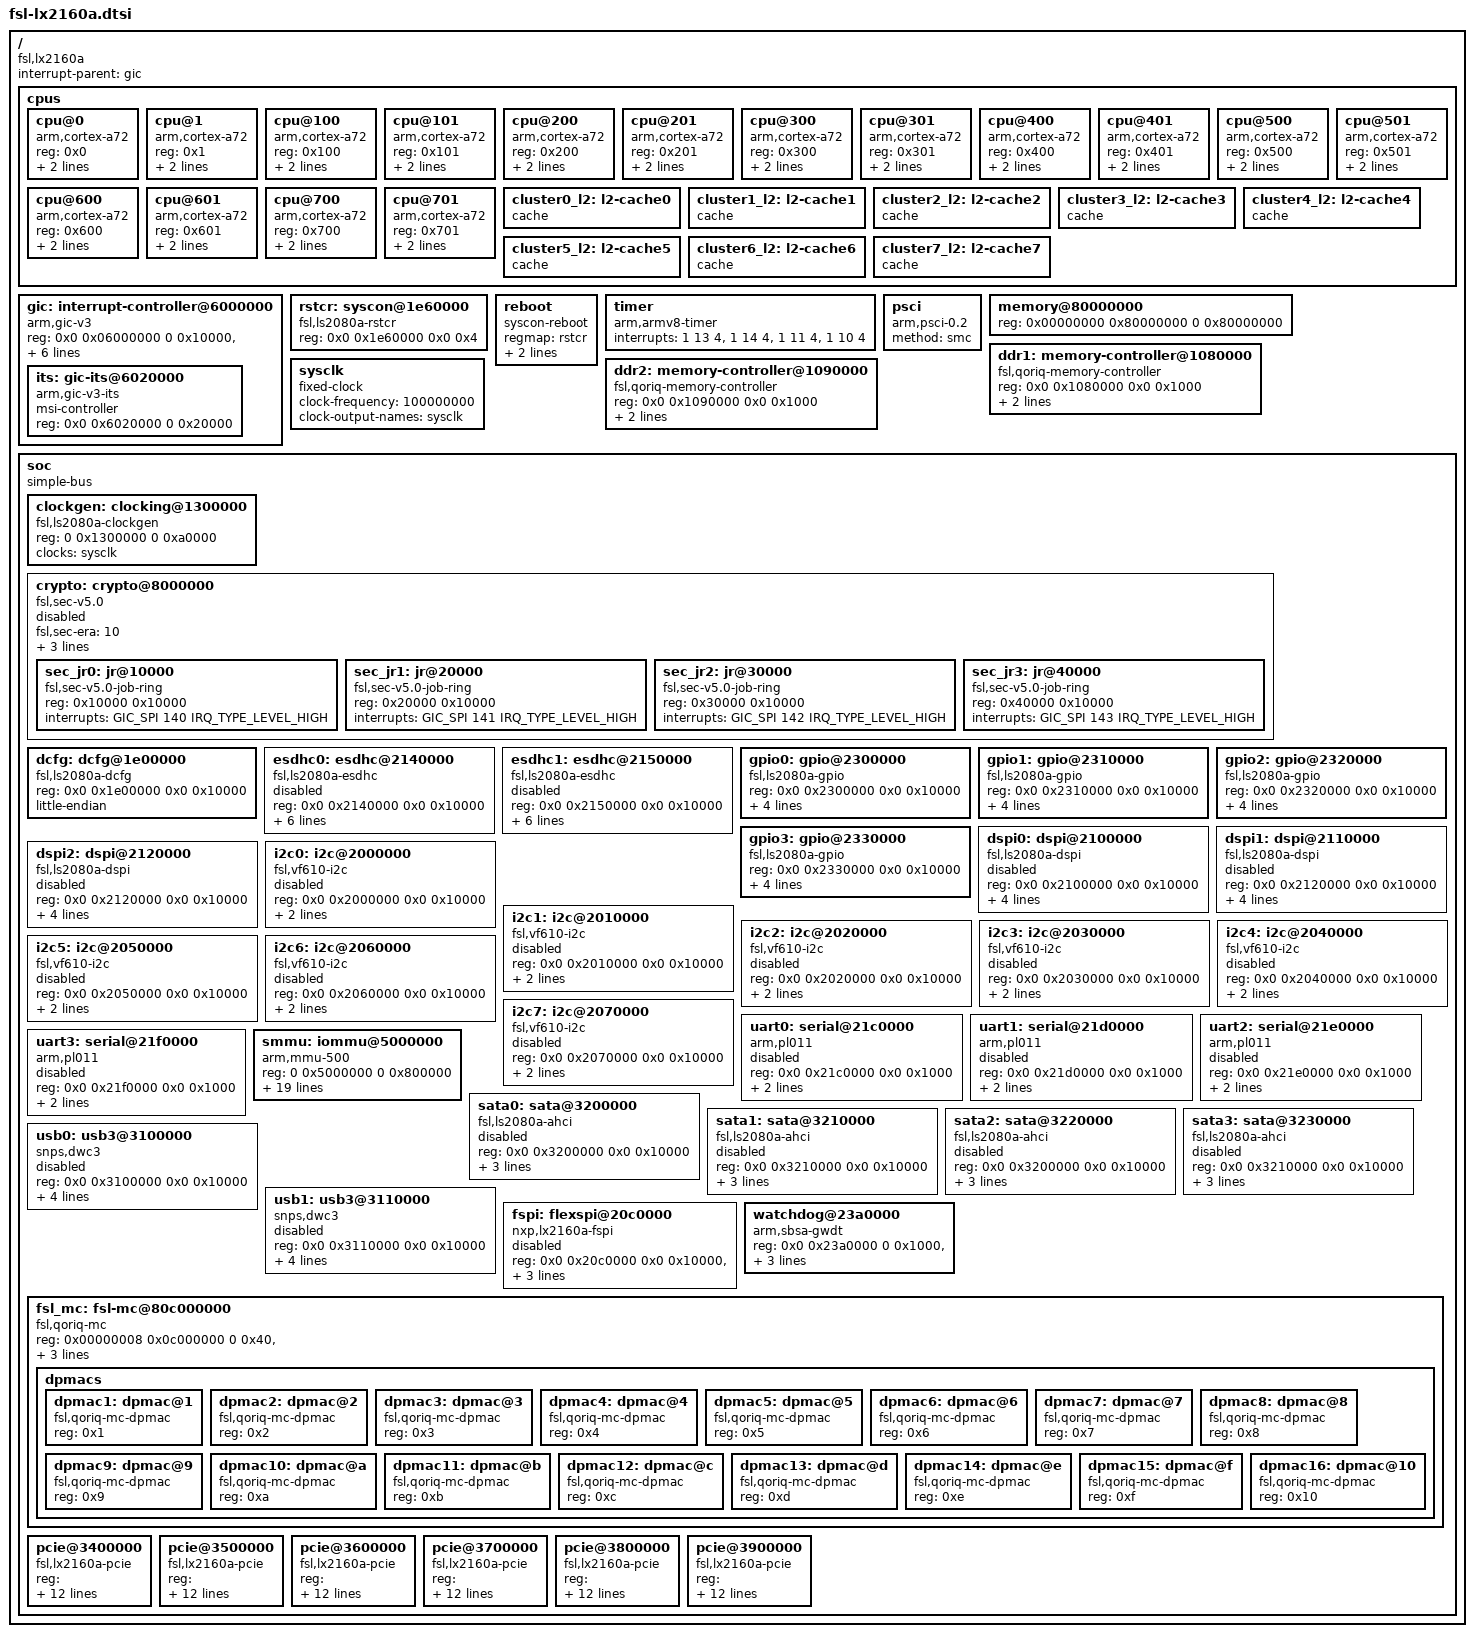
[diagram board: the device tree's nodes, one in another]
/*
 * Device Tree Include file for Layerscape-LX2160A family SoC.
 *
 * Copyright 2018 NXP
 *
 * Sriram Dash <sriram.dash@nxp.com>
 *
 * This file is dual-licensed: you can use it either under the terms
 * of the GPLv2 or the X11 license, at your option. Note that this dual
 * licensing only applies to this file, and not this project as a
 * whole.
 *
 *  a) This library is free software; you can redistribute it and/or
 *     modify it under the terms of the GNU General Public License as
 *     published by the Free Software Foundation; either version 2 of the
 *     License, or (at your option) any later version.
 *
 *     This library is distributed in the hope that it will be useful,
 *     but WITHOUT ANY WARRANTY; without even the implied warranty of
 *     MERCHANTABILITY or FITNESS FOR A PARTICULAR PURPOSE.  See the
 *     GNU General Public License for more details.
 *
 * Or, alternatively,
 *
 *  b) Permission is hereby granted, free of charge, to any person
 *     obtaining a copy of this software and associated documentation
 *     files (the "Software"), to deal in the Software without
 *     restriction, including without limitation the rights to use,
 *     copy, modify, merge, publish, distribute, sublicense, and/or
 *     sell copies of the Software, and to permit persons to whom the
 *     Software is furnished to do so, subject to the following
 *     conditions:
 *
 *     The above copyright notice and this permission notice shall be
 *     included in all copies or substantial portions of the Software.
 *
 *     THE SOFTWARE IS PROVIDED "AS IS", WITHOUT WARRANTY OF ANY KIND,
 *     EXPRESS OR IMPLIED, INCLUDING BUT NOT LIMITED TO THE WARRANTIES
 *     OF MERCHANTABILITY, FITNESS FOR A PARTICULAR PURPOSE AND
 *     NONINFRINGEMENT. IN NO EVENT SHALL THE AUTHORS OR COPYRIGHT
 *     HOLDERS BE LIABLE FOR ANY CLAIM, DAMAGES OR OTHER LIABILITY,
 *     WHETHER IN AN ACTION OF CONTRACT, TORT OR OTHERWISE, ARISING
 *     FROM, OUT OF OR IN CONNECTION WITH THE SOFTWARE OR THE USE OR
 *     OTHER DEALINGS IN THE SOFTWARE.
 */

#include <dt-bindings/interrupt-controller/arm-gic.h>

/memreserve/ 0x80000000 0x00010000;

/ {
	compatible = "fsl,lx2160a";
	interrupt-parent = <&gic>;
	#address-cells = <2>;
	#size-cells = <2>;

	cpus {
		#address-cells = <1>;
		#size-cells = <0>;

		/* We have 8 clusters having 2 Cortex-A72 cores each */
		cpu@0 {
			device_type = "cpu";
			compatible = "arm,cortex-a72";
			reg = <0x0>;
			clocks = <&clockgen 1 0>;
			next-level-cache = <&cluster0_l2>;
		};

		cpu@1 {
			device_type = "cpu";
			compatible = "arm,cortex-a72";
			reg = <0x1>;
			clocks = <&clockgen 1 0>;
			next-level-cache = <&cluster0_l2>;
		};

		cpu@100 {
			device_type = "cpu";
			compatible = "arm,cortex-a72";
			reg = <0x100>;
			clocks = <&clockgen 1 1>;
			next-level-cache = <&cluster1_l2>;
		};

		cpu@101 {
			device_type = "cpu";
			compatible = "arm,cortex-a72";
			reg = <0x101>;
			clocks = <&clockgen 1 1>;
			next-level-cache = <&cluster1_l2>;
		};

		cpu@200 {
			device_type = "cpu";
			compatible = "arm,cortex-a72";
			reg = <0x200>;
			clocks = <&clockgen 1 2>;
			next-level-cache = <&cluster2_l2>;
		};

		cpu@201 {
			device_type = "cpu";
			compatible = "arm,cortex-a72";
			reg = <0x201>;
			clocks = <&clockgen 1 2>;
			next-level-cache = <&cluster2_l2>;
		};

		cpu@300 {
			device_type = "cpu";
			compatible = "arm,cortex-a72";
			reg = <0x300>;
			clocks = <&clockgen 1 3>;
			next-level-cache = <&cluster3_l2>;
		};

		cpu@301 {
			device_type = "cpu";
			compatible = "arm,cortex-a72";
			reg = <0x301>;
			clocks = <&clockgen 1 3>;
			next-level-cache = <&cluster3_l2>;
		};

		cpu@400 {
			device_type = "cpu";
			compatible = "arm,cortex-a72";
			reg = <0x400>;
			clocks = <&clockgen 1 4>;
			next-level-cache = <&cluster4_l2>;
		};

		cpu@401 {
			device_type = "cpu";
			compatible = "arm,cortex-a72";
			reg = <0x401>;
			clocks = <&clockgen 1 4>;
			next-level-cache = <&cluster4_l2>;
		};

		cpu@500 {
			device_type = "cpu";
			compatible = "arm,cortex-a72";
			reg = <0x500>;
			clocks = <&clockgen 1 5>;
			next-level-cache = <&cluster5_l2>;
		};

		cpu@501 {
			device_type = "cpu";
			compatible = "arm,cortex-a72";
			reg = <0x501>;
			clocks = <&clockgen 1 5>;
			next-level-cache = <&cluster5_l2>;
		};

		cpu@600 {
			device_type = "cpu";
			compatible = "arm,cortex-a72";
			reg = <0x600>;
			clocks = <&clockgen 1 6>;
			next-level-cache = <&cluster6_l2>;
		};

		cpu@601 {
			device_type = "cpu";
			compatible = "arm,cortex-a72";
			reg = <0x601>;
			clocks = <&clockgen 1 6>;
			next-level-cache = <&cluster6_l2>;
		};

		cpu@700 {
			device_type = "cpu";
			compatible = "arm,cortex-a72";
			reg = <0x700>;
			clocks = <&clockgen 1 7>;
			next-level-cache = <&cluster7_l2>;
		};

		cpu@701 {
			device_type = "cpu";
			compatible = "arm,cortex-a72";
			reg = <0x701>;
			clocks = <&clockgen 1 7>;
			next-level-cache = <&cluster7_l2>;
		};

		cluster0_l2: l2-cache0 {
			compatible = "cache";
		};

		cluster1_l2: l2-cache1 {
			compatible = "cache";
		};

		cluster2_l2: l2-cache2 {
			compatible = "cache";
		};

		cluster3_l2: l2-cache3 {
			compatible = "cache";
		};

		cluster4_l2: l2-cache4 {
			compatible = "cache";
		};

		cluster5_l2: l2-cache5 {
			compatible = "cache";
		};

		cluster6_l2: l2-cache6 {
			compatible = "cache";
		};

		cluster7_l2: l2-cache7 {
			compatible = "cache";
		};
	};

	gic: interrupt-controller@6000000 {
		compatible = "arm,gic-v3";
		reg = <0x0 0x06000000 0 0x10000>, /* GIC Dist */
			<0x0 0x06200000 0 0x200000>, /* GICR (RD_base + SGI_base) */
			<0x0 0x0c0c0000 0 0x2000>, /* GICC */
			<0x0 0x0c0d0000 0 0x1000>, /* GICH */
			<0x0 0x0c0e0000 0 0x20000>; /* GICV */
		#interrupt-cells = <3>;
		#address-cells = <2>;
		#size-cells = <2>;
		ranges;
		interrupt-controller;
		interrupts = <1 9 0x4>;

		its: gic-its@6020000 {
			compatible = "arm,gic-v3-its";
			msi-controller;
			reg = <0x0 0x6020000 0 0x20000>;
		};
	};

	rstcr: syscon@1e60000 {
		compatible = "fsl,ls2080a-rstcr", "syscon";
		reg = <0x0 0x1e60000 0x0 0x4>;
	};

	reboot {
		compatible ="syscon-reboot";
		regmap = <&rstcr>;
		offset = <0x0>;
		mask = <0x2>;
	};

	timer {
		compatible = "arm,armv8-timer";
		interrupts = <1 13 4>, /* Physical Secure PPI, active-low */
			     <1 14 4>, /* Physical Non-Secure PPI, active-low */
			     <1 11 4>, /* Virtual PPI, active-low */
			     <1 10 4>; /* Hypervisor PPI, active-low */
	};

	psci {
		compatible = "arm,psci-0.2";
		method = "smc";
	};

	memory@80000000 {
		device_type = "memory";
		reg = <0x00000000 0x80000000 0 0x80000000>;
		      /* DRAM space - 1, size : 2 GB DRAM */
	};

	ddr1: memory-controller@1080000 {
		compatible = "fsl,qoriq-memory-controller";
		reg = <0x0 0x1080000 0x0 0x1000>;
		interrupts = <0 17 0x4>;
		little-endian;
	};

	ddr2: memory-controller@1090000 {
		compatible = "fsl,qoriq-memory-controller";
		reg = <0x0 0x1090000 0x0 0x1000>;
		interrupts = <0 18 0x4>;
		little-endian;
	};

	sysclk: sysclk {
		compatible = "fixed-clock";
		#clock-cells = <0>;
		clock-frequency = <100000000>;
		clock-output-names = "sysclk";
	};

	soc {
		compatible = "simple-bus";
		#address-cells = <2>;
		#size-cells = <2>;
		ranges;

		clockgen: clocking@1300000 {
			compatible = "fsl,ls2080a-clockgen";
			reg = <0 0x1300000 0 0xa0000>;
			#clock-cells = <2>;
			clocks = <&sysclk>;
		};

		crypto: crypto@8000000 {
			compatible = "fsl,sec-v5.0", "fsl,sec-v4.0";
			fsl,sec-era = <10>;
			#address-cells = <1>;
			#size-cells = <1>;
			ranges = <0x0 0x00 0x8000000 0x100000>;
			reg = <0x00 0x8000000 0x0 0x100000>;
			interrupts = <GIC_SPI 139 IRQ_TYPE_LEVEL_HIGH>;
			dma-coherent;
			status = "disabled";

			sec_jr0: jr@10000 {
				compatible = "fsl,sec-v5.0-job-ring",
					     "fsl,sec-v4.0-job-ring";
				reg	   = <0x10000 0x10000>;
				interrupts = <GIC_SPI 140 IRQ_TYPE_LEVEL_HIGH>;
			};

			sec_jr1: jr@20000 {
				compatible = "fsl,sec-v5.0-job-ring",
					     "fsl,sec-v4.0-job-ring";
				reg	   = <0x20000 0x10000>;
				interrupts = <GIC_SPI 141 IRQ_TYPE_LEVEL_HIGH>;
			};

			sec_jr2: jr@30000 {
				compatible = "fsl,sec-v5.0-job-ring",
					     "fsl,sec-v4.0-job-ring";
				reg	   = <0x30000 0x10000>;
				interrupts = <GIC_SPI 142 IRQ_TYPE_LEVEL_HIGH>;
			};

			sec_jr3: jr@40000 {
				compatible = "fsl,sec-v5.0-job-ring",
					     "fsl,sec-v4.0-job-ring";
				reg	   = <0x40000 0x10000>;
				interrupts = <GIC_SPI 143 IRQ_TYPE_LEVEL_HIGH>;
			};
		};

		dcfg: dcfg@1e00000 {
			compatible = "fsl,ls2080a-dcfg", "syscon";
			reg = <0x0 0x1e00000 0x0 0x10000>;
			little-endian;
		};

		esdhc0: esdhc@2140000 {
			status = "disabled";
			compatible = "fsl,ls2080a-esdhc", "fsl,esdhc";
			reg = <0x0 0x2140000 0x0 0x10000>;
			interrupts = <0 28 0x4>; /* Level high type */
			clocks = <&clockgen 4 1>;
			voltage-ranges = <1800 1800 3300 3300>;
			sdhci,auto-cmd12;
			little-endian;
			bus-width = <4>;
		};

		esdhc1: esdhc@2150000 {
			status = "disabled";
			compatible = "fsl,ls2080a-esdhc", "fsl,esdhc";
			reg = <0x0 0x2150000 0x0 0x10000>;
			interrupts = <0 28 0x4>; /* Level high type */
			clocks = <&clockgen 4 1>;
			voltage-ranges = <1800 1800 3300 3300>;
			sdhci,auto-cmd12;
			little-endian;
			bus-width = <4>;
		};

		gpio0: gpio@2300000 {
			compatible = "fsl,ls2080a-gpio", "fsl,qoriq-gpio";
			reg = <0x0 0x2300000 0x0 0x10000>;
			interrupts = <0 36 0x4>; /* Level high type */
			gpio-controller;
			little-endian;
			#gpio-cells = <2>;
			interrupt-controller;
			#interrupt-cells = <2>;
		};

		gpio1: gpio@2310000 {
			compatible = "fsl,ls2080a-gpio", "fsl,qoriq-gpio";
			reg = <0x0 0x2310000 0x0 0x10000>;
			interrupts = <0 36 0x4>; /* Level high type */
			gpio-controller;
			little-endian;
			#gpio-cells = <2>;
			interrupt-controller;
			#interrupt-cells = <2>;
		};

		gpio2: gpio@2320000 {
			compatible = "fsl,ls2080a-gpio", "fsl,qoriq-gpio";
			reg = <0x0 0x2320000 0x0 0x10000>;
			interrupts = <0 37 0x4>; /* Level high type */
			gpio-controller;
			little-endian;
			#gpio-cells = <2>;
			interrupt-controller;
			#interrupt-cells = <2>;
		};

		gpio3: gpio@2330000 {
			compatible = "fsl,ls2080a-gpio", "fsl,qoriq-gpio";
			reg = <0x0 0x2330000 0x0 0x10000>;
			interrupts = <0 37 0x4>; /* Level high type */
			gpio-controller;
			little-endian;
			#gpio-cells = <2>;
			interrupt-controller;
			#interrupt-cells = <2>;
		};

		dspi0: dspi@2100000 {
			status = "disabled";
			compatible = "fsl,ls2080a-dspi", "fsl,ls2085a-dspi";
			#address-cells = <1>;
			#size-cells = <0>;
			reg = <0x0 0x2100000 0x0 0x10000>;
			interrupts = <0 26 0x4>; /* Level high type */
			clocks = <&clockgen 4 3>;
			clock-names = "dspi";
			spi-num-chipselects = <5>;
			bus-num = <0>;
		};

		dspi1: dspi@2110000 {
			status = "disabled";
			compatible = "fsl,ls2080a-dspi", "fsl,ls2085a-dspi";
			#address-cells = <1>;
			#size-cells = <0>;
			reg = <0x0 0x2120000 0x0 0x10000>;
			interrupts = <0 240 0x4>; /* Level high type */
			clocks = <&clockgen 4 3>;
			clock-names = "dspi";
			spi-num-chipselects = <5>;
			bus-num = <0>;
		};

		dspi2: dspi@2120000 {
			status = "disabled";
			compatible = "fsl,ls2080a-dspi", "fsl,ls2085a-dspi";
			#address-cells = <1>;
			#size-cells = <0>;
			reg = <0x0 0x2120000 0x0 0x10000>;
			interrupts = <0 241 0x4>; /* Level high type */
			clocks = <&clockgen 4 3>;
			clock-names = "dspi";
			spi-num-chipselects = <5>;
			bus-num = <0>;
		};


		i2c0: i2c@2000000 {
			compatible = "fsl,vf610-i2c";
			#address-cells = <1>;
			#size-cells = <0>;
			reg = <0x0 0x2000000 0x0 0x10000>;
			interrupts = <0 34 0x4>; /* Level high type */
			clock-names = "i2c";
			clocks = <&clockgen 4 3>;
			status = "disabled";
		};

		i2c1: i2c@2010000 {
			compatible = "fsl,vf610-i2c";
			#address-cells = <1>;
			#size-cells = <0>;
			reg = <0x0 0x2010000 0x0 0x10000>;
			interrupts = <0 34 0x4>; /* Level high type */
			clock-names = "i2c";
			clocks = <&clockgen 4 3>;
			status = "disabled";
		};

		i2c2: i2c@2020000 {
			compatible = "fsl,vf610-i2c";
			#address-cells = <1>;
			#size-cells = <0>;
			reg = <0x0 0x2020000 0x0 0x10000>;
			interrupts = <0 35 0x4>; /* Level high type */
			clock-names = "i2c";
			clocks = <&clockgen 4 3>;
			status = "disabled";
		};

		i2c3: i2c@2030000 {
			compatible = "fsl,vf610-i2c";
			#address-cells = <1>;
			#size-cells = <0>;
			reg = <0x0 0x2030000 0x0 0x10000>;
			interrupts = <0 35 0x4>; /* Level high type */
			clock-names = "i2c";
			clocks = <&clockgen 4 3>;
			status = "disabled";
		};

		i2c4: i2c@2040000 {
			compatible = "fsl,vf610-i2c";
			#address-cells = <1>;
			#size-cells = <0>;
			reg = <0x0 0x2040000 0x0 0x10000>;
			interrupts = <0 74 0x4>; /* Level high type */
			clock-names = "i2c";
			clocks = <&clockgen 4 3>;
			status = "disabled";
		};

		i2c5: i2c@2050000 {
			compatible = "fsl,vf610-i2c";
			#address-cells = <1>;
			#size-cells = <0>;
			reg = <0x0 0x2050000 0x0 0x10000>;
			interrupts = <0 74 0x4>; /* Level high type */
			clock-names = "i2c";
			clocks = <&clockgen 4 3>;
			status = "disabled";
		};

		i2c6: i2c@2060000 {
			compatible = "fsl,vf610-i2c";
			#address-cells = <1>;
			#size-cells = <0>;
			reg = <0x0 0x2060000 0x0 0x10000>;
			interrupts = <0 75 0x4>; /* Level high type */
			clock-names = "i2c";
			clocks = <&clockgen 4 3>;
			status = "disabled";
		};

		i2c7: i2c@2070000 {
			compatible = "fsl,vf610-i2c";
			#address-cells = <1>;
			#size-cells = <0>;
			reg = <0x0 0x2070000 0x0 0x10000>;
			interrupts = <0 75 0x4>; /* Level high type */
			clock-names = "i2c";
			clocks = <&clockgen 4 3>;
			status = "disabled";
		};

		uart0: serial@21c0000 {
			device_type = "serial";
			compatible = "arm,pl011","arm,sbsa-uart";
			reg = <0x0 0x21c0000 0x0 0x1000>;
			interrupts = <0 32 0x4>;	/* Level high type */
			current-speed = <115200>;
			status = "disabled";
		};

		uart1: serial@21d0000 {
			device_type = "serial";
			compatible = "arm,pl011","arm,sbsa-uart";
			reg = <0x0 0x21d0000 0x0 0x1000>;
			interrupts = <0 33 0x4>;	/* Level high type */
			current-speed = <115200>;
			status = "disabled";
		};

		uart2: serial@21e0000 {
			device_type = "serial";
			compatible = "arm,pl011","arm,sbsa-uart";
			reg = <0x0 0x21e0000 0x0 0x1000>;
			interrupts = <0 72 0x4>;	/* Level high type */
			current-speed = <115200>;
			status = "disabled";
		};

		uart3: serial@21f0000 {
			device_type = "serial";
			compatible = "arm,pl011","arm,sbsa-uart";
			reg = <0x0 0x21f0000 0x0 0x1000>;
			interrupts = <0 73 0x4>;	/* Level high type */
			current-speed = <115200>;
			status = "disabled";
		};

		smmu: iommu@5000000 {
			compatible = "arm,mmu-500";
			reg = <0 0x5000000 0 0x800000>;
			#iommu-cells = <1>;
			stream-match-mask = <0x7C00>;
			#global-interrupts = <14>;
			interrupts = <0 13 4>, /* global secure fault */
				     <0 14 4>, /* combined secure interrupt */
				     <0 15 4>, /* global non-secure fault */
				     <0 16 4>, /* combined non-secure interrupt */
				/* performance counter interrupts 0-9 */
				     <0 211 4>, <0 212 4>,
				     <0 213 4>, <0 214 4>,
				     <0 215 4>, <0 216 4>,
				     <0 217 4>, <0 218 4>,
				     <0 219 4>, <0 220 4>,
				/* per context interrupt, 64 interrupts */
				     <0 146 4>, <0 147 4>,
				     <0 148 4>, <0 149 4>,
				     <0 150 4>, <0 151 4>,
				     <0 152 4>, <0 153 4>,
				     <0 154 4>, <0 155 4>,
				     <0 156 4>, <0 157 4>,
				     <0 158 4>, <0 159 4>,
				     <0 160 4>, <0 161 4>,
				     <0 162 4>, <0 163 4>,
				     <0 164 4>, <0 165 4>,
				     <0 166 4>, <0 167 4>,
				     <0 168 4>, <0 169 4>,
				     <0 170 4>, <0 171 4>,
				     <0 172 4>, <0 173 4>,
				     <0 174 4>, <0 175 4>,
				     <0 176 4>, <0 177 4>,
				     <0 178 4>, <0 179 4>,
				     <0 180 4>, <0 181 4>,
				     <0 182 4>, <0 183 4>,
				     <0 184 4>, <0 185 4>,
				     <0 186 4>, <0 187 4>,
				     <0 188 4>, <0 189 4>,
				     <0 190 4>, <0 191 4>,
				     <0 192 4>, <0 193 4>,
				     <0 194 4>, <0 195 4>,
				     <0 196 4>, <0 197 4>,
				     <0 198 4>, <0 199 4>,
				     <0 200 4>, <0 201 4>,
				     <0 202 4>, <0 203 4>,
				     <0 204 4>, <0 205 4>,
				     <0 206 4>, <0 207 4>,
				     <0 208 4>, <0 209 4>;
			dma-coherent;
		};

		sata0: sata@3200000 {
			status = "disabled";
			compatible = "fsl,ls2080a-ahci";
			reg = <0x0 0x3200000 0x0 0x10000>;
			interrupts = <0 133 0x4>; /* Level high type */
			clocks = <&clockgen 4 3>;
			dma-coherent;
		};

		sata1: sata@3210000 {
			status = "disabled";
			compatible = "fsl,ls2080a-ahci";
			reg = <0x0 0x3210000 0x0 0x10000>;
			interrupts = <0 136 0x4>; /* Level high type */
			clocks = <&clockgen 4 3>;
			dma-coherent;
		};

		sata2: sata@3220000 {
			status = "disabled";
			compatible = "fsl,ls2080a-ahci";
			reg = <0x0 0x3200000 0x0 0x10000>;
			interrupts = <0 97 0x4>; /* Level high type */
			clocks = <&clockgen 4 3>;
			dma-coherent;
		};

		sata3: sata@3230000 {
			status = "disabled";
			compatible = "fsl,ls2080a-ahci";
			reg = <0x0 0x3210000 0x0 0x10000>;
			interrupts = <0 100 0x4>; /* Level high type */
			clocks = <&clockgen 4 3>;
			dma-coherent;
		};

		usb0: usb3@3100000 {
			status = "disabled";
			compatible = "snps,dwc3";
			reg = <0x0 0x3100000 0x0 0x10000>;
			interrupts = <0 80 0x4>; /* Level high type */
			dr_mode = "host";
			snps,quirk-frame-length-adjustment = <0x20>;
			snps,dis_rxdet_inp3_quirk;
		};

		usb1: usb3@3110000 {
			status = "disabled";
			compatible = "snps,dwc3";
			reg = <0x0 0x3110000 0x0 0x10000>;
			interrupts = <0 81 0x4>; /* Level high type */
			dr_mode = "host";
			snps,quirk-frame-length-adjustment = <0x20>;
			snps,dis_rxdet_inp3_quirk;
		};

		fspi: flexspi@20c0000 {
			status = "disabled";
			compatible = "nxp,lx2160a-fspi";
			#address-cells = <1>;
			#size-cells = <0>;
			reg = <0x0 0x20c0000 0x0 0x10000>,
				<0x0 0x20000000 0x0 0x10000000>;
			reg-names = "FSPI", "FSPI-memory";
			interrupts = <0 25 0x4>; /* Level high type */
			clocks = <&clockgen 4 3>, <&clockgen 4 3>;
			clock-names = "fspi_en", "fspi";
		};

		watchdog@23a0000 {
			compatible = "arm,sbsa-gwdt";
			reg = <0x0 0x23a0000 0 0x1000>,
			      <0x0 0x2390000 0 0x1000>;
			interrupts = <0 59 4>;
			timeout-sec = <30>;
		};

		fsl_mc: fsl-mc@80c000000 {
			compatible = "fsl,qoriq-mc";
			reg = <0x00000008 0x0c000000 0 0x40>,
			      <0x00000000 0x08340000 0 0x40000>;
			msi-parent = <&its>;
			/* iommu-map property is fixed up by u-boot */
			iommu-map = <0 &smmu 0 0>;
			#address-cells = <3>;
			#size-cells = <1>;

			/*
			 * Region type 0x0 - MC portals
			 * Region type 0x1 - QBMAN portals
			 */
			ranges = <0x0 0x0 0x0 0x8 0x0c000000 0x4000000
				  0x1 0x0 0x0 0x8 0x18000000 0x8000000>;

			/*
			 * Define the maximum number of MACs present on the SoC.
			 */
			dpmacs {
				#address-cells = <1>;
				#size-cells = <0>;

				dpmac1: dpmac@1 {
					compatible = "fsl,qoriq-mc-dpmac";
					reg = <0x1>;
				};

				dpmac2: dpmac@2 {
					compatible = "fsl,qoriq-mc-dpmac";
					reg = <0x2>;
				};

				dpmac3: dpmac@3 {
					compatible = "fsl,qoriq-mc-dpmac";
					reg = <0x3>;
				};

				dpmac4: dpmac@4 {
					compatible = "fsl,qoriq-mc-dpmac";
					reg = <0x4>;
				};

				dpmac5: dpmac@5 {
					compatible = "fsl,qoriq-mc-dpmac";
					reg = <0x5>;
				};

				dpmac6: dpmac@6 {
					compatible = "fsl,qoriq-mc-dpmac";
					reg = <0x6>;
				};

				dpmac7: dpmac@7 {
					compatible = "fsl,qoriq-mc-dpmac";
					reg = <0x7>;
				};

				dpmac8: dpmac@8 {
					compatible = "fsl,qoriq-mc-dpmac";
					reg = <0x8>;
				};

				dpmac9: dpmac@9 {
					compatible = "fsl,qoriq-mc-dpmac";
					reg = <0x9>;
				};

				dpmac10: dpmac@a {
					compatible = "fsl,qoriq-mc-dpmac";
					reg = <0xa>;
				};

				dpmac11: dpmac@b {
					compatible = "fsl,qoriq-mc-dpmac";
					reg = <0xb>;
				};

				dpmac12: dpmac@c {
					compatible = "fsl,qoriq-mc-dpmac";
					reg = <0xc>;
				};

				dpmac13: dpmac@d {
					compatible = "fsl,qoriq-mc-dpmac";
					reg = <0xd>;
				};

				dpmac14: dpmac@e {
					compatible = "fsl,qoriq-mc-dpmac";
					reg = <0xe>;
				};

				dpmac15: dpmac@f {
					compatible = "fsl,qoriq-mc-dpmac";
					reg = <0xf>;
				};

				dpmac16: dpmac@10 {
					compatible = "fsl,qoriq-mc-dpmac";
					reg = <0x10>;
				};
			};
		};

		pcie@3400000 {
			compatible = "fsl,lx2160a-pcie";
			reg = <0x00 0x03400000 0x0 0x00100000   /* controller registers */
			       0x80 0x00000000 0x0 0x00020000>; /* configuration space */
			reg-names = "regs", "config";
			interrupts = <0 108 0x4>, /* AER interrupt */
				     <0 108 0x4>; /* PME interrupt */
			interrupt-names = "aer", "pme";
			#address-cells = <3>;
			#size-cells = <2>;
			device_type = "pci";
			dma-coherent;
			apio-wins = <3>;
			ppio-wins-rc = <3>;
			bus-range = <0x0 0xff>;
			ranges = <0x81000000 0x0 0x00000000 0x80 0x00020000 0x0 0x00010000   /* downstream I/O */
				  0x82000000 0x0 0x40000000 0x80 0x40000000 0x0 0x40000000>; /* non-prefetchable memory */
			msi-parent = <&its>;
			#interrupt-cells = <1>;
			interrupt-map-mask = <0 0 0 7>;
			interrupt-map = <0000 0 0 1 &gic 0 0 0 109 0x4>,
					<0000 0 0 2 &gic 0 0 0 110 0x4>,
					<0000 0 0 3 &gic 0 0 0 111 0x4>,
					<0000 0 0 4 &gic 0 0 0 112 0x4>;
		};

		pcie@3500000 {
			compatible = "fsl,lx2160a-pcie";
			reg = <0x00 0x03500000 0x0 0x00100000   /* controller registers */
			       0x88 0x00000000 0x0 0x00020000>; /* configuration space */
			reg-names = "regs", "config";
			interrupts = <0 113 0x4>, /* AER interrupt */
				     <0 113 0x4>; /* PME interrupt */
			interrupt-names = "aer", "pme";
			#address-cells = <3>;
			#size-cells = <2>;
			device_type = "pci";
			dma-coherent;
			apio-wins = <3>;
			ppio-wins-rc = <3>;
			bus-range = <0x0 0xff>;
			ranges = <0x81000000 0x0 0x00000000 0x88 0x00020000 0x0 0x00010000   /* downstream I/O */
				  0x82000000 0x0 0x40000000 0x88 0x40000000 0x0 0x40000000>; /* non-prefetchable memory */
			msi-parent = <&its>;
			#interrupt-cells = <1>;
			interrupt-map-mask = <0 0 0 7>;
			interrupt-map = <0000 0 0 1 &gic 0 0 0 114 0x4>,
					<0000 0 0 2 &gic 0 0 0 115 0x4>,
					<0000 0 0 3 &gic 0 0 0 116 0x4>,
					<0000 0 0 4 &gic 0 0 0 117 0x4>;
		};

		pcie@3600000 {
			compatible = "fsl,lx2160a-pcie";
			reg = <0x00 0x03600000 0x0 0x00100000   /* controller registers */
			       0x90 0x00000000 0x0 0x00020000>; /* configuration space */
			reg-names = "regs", "config";
			interrupts = <0 118 0x4>, /* AER interrupt */
				     <0 118 0x4>; /* PME interrupt */
			interrupt-names = "aer", "pme";
			#address-cells = <3>;
			#size-cells = <2>;
			device_type = "pci";
			dma-coherent;
			apio-wins = <3>;
			ppio-wins-rc = <3>;
			bus-range = <0x0 0xff>;
			ranges = <0x81000000 0x0 0x00000000 0x90 0x00020000 0x0 0x00010000   /* downstream I/O */
				  0x82000000 0x0 0x40000000 0x90 0x40000000 0x0 0x40000000>; /* non-prefetchable memory */
			msi-parent = <&its>;
			#interrupt-cells = <1>;
			interrupt-map-mask = <0 0 0 7>;
			interrupt-map = <0000 0 0 1 &gic 0 0 0 119 0x4>,
					<0000 0 0 2 &gic 0 0 0 120 0x4>,
					<0000 0 0 3 &gic 0 0 0 121 0x4>,
					<0000 0 0 4 &gic 0 0 0 122 0x4>;
		};

		pcie@3700000 {
			compatible = "fsl,lx2160a-pcie";
			reg = <0x00 0x03700000 0x0 0x00100000   /* controller registers */
			       0x98 0x00000000 0x0 0x00020000>; /* configuration space */
			reg-names = "regs", "config";
			interrupts = <0 123 0x4>, /* AER interrupt */
				     <0 123 0x4>; /* PME interrupt */
			interrupt-names = "aer", "pme";
			#address-cells = <3>;
			#size-cells = <2>;
			device_type = "pci";
			dma-coherent;
			apio-wins = <3>;
			ppio-wins-rc = <3>;
			bus-range = <0x0 0xff>;
			ranges = <0x81000000 0x0 0x00000000 0x98 0x00020000 0x0 0x00010000   /* downstream I/O */
				  0x82000000 0x0 0x40000000 0x98 0x40000000 0x0 0x40000000>; /* non-prefetchable memory */
			msi-parent = <&its>;
			#interrupt-cells = <1>;
			interrupt-map-mask = <0 0 0 7>;
			interrupt-map = <0000 0 0 1 &gic 0 0 0 124 0x4>,
					<0000 0 0 2 &gic 0 0 0 125 0x4>,
					<0000 0 0 3 &gic 0 0 0 126 0x4>,
					<0000 0 0 4 &gic 0 0 0 127 0x4>;
		};

		pcie@3800000 {
			compatible = "fsl,lx2160a-pcie";
			reg = <0x00 0x03800000 0x0 0x00100000   /* controller registers */
			       0xa0 0x00000000 0x0 0x00020000>; /* configuration space */
			reg-names = "regs", "config";
			interrupts = <0 128 0x4>, /* AER interrupt */
				     <0 128 0x4>; /* PME interrupt */
			interrupt-names = "aer", "pme";
			#address-cells = <3>;
			#size-cells = <2>;
			device_type = "pci";
			dma-coherent;
			apio-wins = <3>;
			ppio-wins-rc = <3>;
			bus-range = <0x0 0xff>;
			ranges = <0x81000000 0x0 0x00000000 0xa0 0x00020000 0x0 0x00010000   /* downstream I/O */
				  0x82000000 0x0 0x40000000 0xa0 0x40000000 0x0 0x40000000>; /* non-prefetchable memory */
			msi-parent = <&its>;
			#interrupt-cells = <1>;
			interrupt-map-mask = <0 0 0 7>;
			interrupt-map = <0000 0 0 1 &gic 0 0 0 129 0x4>,
					<0000 0 0 2 &gic 0 0 0 130 0x4>,
					<0000 0 0 3 &gic 0 0 0 131 0x4>,
					<0000 0 0 4 &gic 0 0 0 132 0x4>;
		};

		pcie@3900000 {
			compatible = "fsl,lx2160a-pcie";
			reg = <0x00 0x03900000 0x0 0x00100000   /* controller registers */
			       0xa8 0x00000000 0x0 0x00020000>; /* configuration space */
			reg-names = "regs", "config";
			interrupts = <0 103 0x4>, /* AER interrupt */
				     <0 103 0x4>; /* PME interrupt */
			interrupt-names = "aer", "pme";
			#address-cells = <3>;
			#size-cells = <2>;
			device_type = "pci";
			dma-coherent;
			apio-wins = <3>;
			ppio-wins-rc = <3>;
			bus-range = <0x0 0xff>;
			ranges = <0x81000000 0x0 0x00000000 0xa8 0x00020000 0x0 0x00010000   /* downstream I/O */
				  0x82000000 0x0 0x40000000 0xa8 0x40000000 0x0 0x40000000>; /* non-prefetchable memory */
			msi-parent = <&its>;
			#interrupt-cells = <1>;
			interrupt-map-mask = <0 0 0 7>;
			interrupt-map = <0000 0 0 1 &gic 0 0 0 104 0x4>,
					<0000 0 0 2 &gic 0 0 0 105 0x4>,
					<0000 0 0 3 &gic 0 0 0 106 0x4>,
					<0000 0 0 4 &gic 0 0 0 107 0x4>;
		};

	};
};
